# STM32G07x register map
File version: 1.3
CPU: CM0+ r0p0, little endian, no MPU, no FPU, 3 interrupt priority bits
Registers are 32-bit, read-write, reset 0x0 unless marked. A register's access mark holds for its fields unless they carry their own. Offsets are from the block's base; [hi:lo] are bit positions.

## IWDG — Independent watchdog
Base 0x40003000
0x00 KR wo — Key register
  [15:0] KEY — Key value (write only, read 0x0000)
0x04 PR — Prescaler register
  [2:0] PR — Prescaler divider
0x08 RLR reset 0xFFF — Reload register
  [11:0] RL — Watchdog counter reload value
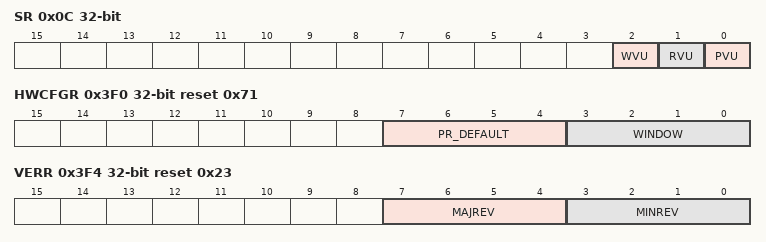
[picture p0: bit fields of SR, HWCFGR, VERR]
0x0C SR ro — Status register
  [2] WVU — Watchdog counter window value update
  [1] RVU — Watchdog counter reload value update
  [0] PVU — Watchdog prescaler value update
0x10 WINR reset 0xFFF — Window register
  [11:0] WIN — Watchdog counter window value
0x3F0 HWCFGR reset 0x71 — hardware configuration register
  [7:4] PR_DEFAULT — Prescaler default value
  [3:0] WINDOW — Support of Window function
0x3F4 VERR ro reset 0x23 — EXTI IP Version register
  [7:4] MAJREV — Major Revision number
  [3:0] MINREV — Minor Revision number
0x3F8 IPIDR ro reset 0x120041 — EXTI Identification register
  [31:0] IPID — IP Identification
0x3FC SIDR ro reset 0xA3C5DD01 — EXTI Size ID register
  [31:0] SID — Size Identification

## WWDG — System window watchdog
Base 0x40002C00
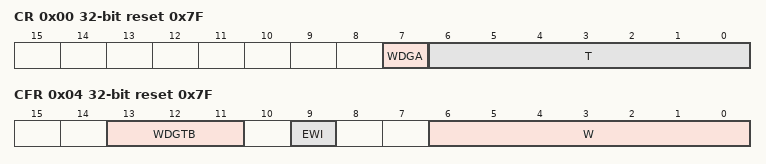
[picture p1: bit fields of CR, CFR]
0x00 CR reset 0x7F — Control register
  [7] WDGA — Activation bit
  [6:0] T — 7-bit counter (MSB to LSB)
0x04 CFR reset 0x7F — Configuration register
  [13:11] WDGTB — Timer base
  [9] EWI — Early wakeup interrupt
  [6:0] W — 7-bit window value
0x08 SR — Status register
  [0] EWIF — Early wakeup interrupt flag

## FLASH
Base 0x40022000
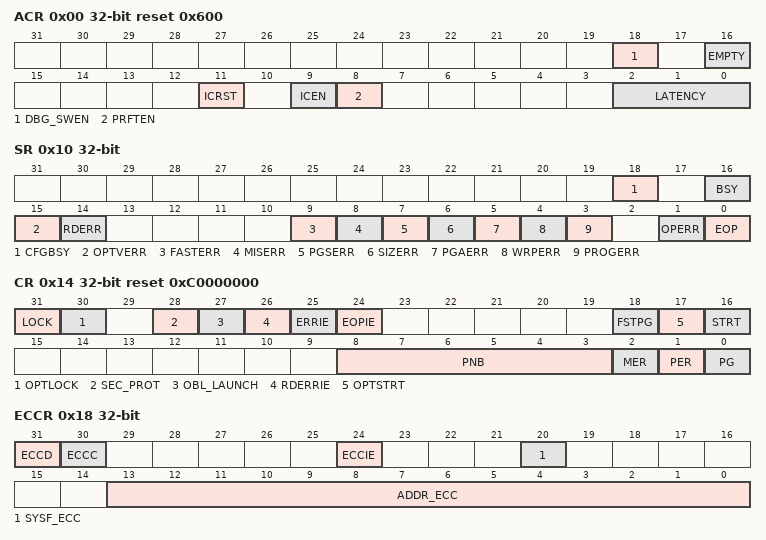
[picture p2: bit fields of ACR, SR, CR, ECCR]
0x00 ACR reset 0x600 — Access control register
  [18] DBG_SWEN — Debug access software enable
  [16] EMPTY — Flash User area empty
  [11] ICRST — Instruction cache reset
  [9] ICEN — Instruction cache enable
  [8] PRFTEN — Prefetch enable
  [2:0] LATENCY
0x08 KEYR wo — Flash key register
0x0C OPTKEYR wo — Option byte key register
  [31:0] OPTKEYR — Option byte key
0x10 SR — Status register
  [18] CFGBSY — Programming or erase configuration busy.
  [16] BSY — Busy
  [15] OPTVERR — Option and Engineering bits loading validity error
  [14] RDERR — PCROP read error
  [9] FASTERR — Fast programming error
  [8] MISERR — Fast programming data miss error
  [7] PGSERR — Programming sequence error
  [6] SIZERR — Size error
  [5] PGAERR — Programming alignment error
  [4] WRPERR — Write protected error
  [3] PROGERR — Programming error
  [1] OPERR — Operation error
  [0] EOP — End of operation
0x14 CR reset 0xC0000000 — Flash control register
  [31] LOCK — FLASH_CR Lock
  [30] OPTLOCK — Options Lock
  [28] SEC_PROT — Securable memory area protection enable
  [27] OBL_LAUNCH — Force the option byte loading
  [26] RDERRIE — PCROP read error interrupt enable
  [25] ERRIE — Error interrupt enable
  [24] EOPIE — End of operation interrupt enable
  [18] FSTPG — Fast programming
  [17] OPTSTRT — Options modification start
  [16] STRT — Start
  [8:3] PNB — Page number
  [2] MER — Mass erase
  [1] PER — Page erase
  [0] PG — Programming
0x18 ECCR access per field — Flash ECC register
  [31] ECCD rw — ECC detection
  [30] ECCC rw — ECC correction
  [24] ECCIE rw — ECC correction interrupt enable
  [20] SYSF_ECC ro — ECC fail for Corrected ECC Error or Double ECC Error in info block
  [13:0] ADDR_ECC ro — ECC fail address
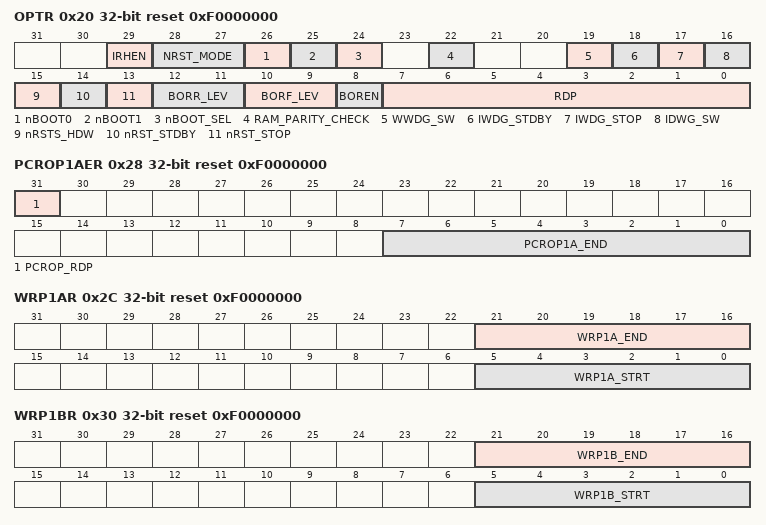
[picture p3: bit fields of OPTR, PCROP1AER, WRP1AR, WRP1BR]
0x20 OPTR reset 0xF0000000 — Flash option register
  [29] IRHEN — Internal reset holder enable bit
  [28:27] NRST_MODE
  [26] nBOOT0 — nBOOT0 option bit
  [25] nBOOT1 — Boot configuration
  [24] nBOOT_SEL
  [22] RAM_PARITY_CHECK — SRAM parity check control
  [19] WWDG_SW — Window watchdog selection
  [18] IWDG_STDBY — Independent watchdog counter freeze in Standby mode
  [17] IWDG_STOP — Independent watchdog counter freeze in Stop mode
  [16] IDWG_SW — Independent watchdog selection
  [15] nRSTS_HDW
  [14] nRST_STDBY
  [13] nRST_STOP
  [12:11] BORR_LEV — These bits contain the VDD supply level threshold that releases the reset.
  [10:9] BORF_LEV — These bits contain the VDD supply level threshold that activates the reset
  [8] BOREN — BOR reset Level
  [7:0] RDP — Read protection level
0x24 PCROP1ASR ro reset 0xF0000000 — Flash PCROP zone A Start address register
  [7:0] PCROP1A_STRT — PCROP1A area start offset
0x28 PCROP1AER ro reset 0xF0000000 — Flash PCROP zone A End address register
  [31] PCROP_RDP — PCROP area preserved when RDP level decreased
  [7:0] PCROP1A_END — PCROP1A area end offset
0x2C WRP1AR ro reset 0xF0000000 — Flash WRP area A address register
  [21:16] WRP1A_END — WRP area A end offset
  [5:0] WRP1A_STRT — WRP area A start offset
0x30 WRP1BR ro reset 0xF0000000 — Flash WRP area B address register
  [21:16] WRP1B_END — WRP area B end offset
  [5:0] WRP1B_STRT — WRP area B start offset
0x34 PCROP1BSR ro reset 0xF0000000 — Flash PCROP zone B Start address register
  [7:0] PCROP1B_STRT — PCROP1B area start offset
0x38 PCROP1BER ro reset 0xF0000000 — Flash PCROP zone B End address register
  [7:0] PCROP1B_END — PCROP1B area end offset
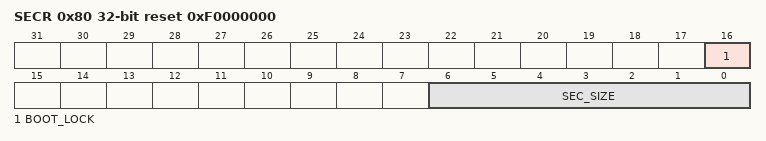
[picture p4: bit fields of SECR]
0x80 SECR ro reset 0xF0000000 — Flash Security register
  [16] BOOT_LOCK — used to force boot from user area
  [6:0] SEC_SIZE — Securable memory area size
